# WKUP_CTRL_MMR1_CFG0 register map
Vendor: Texas Instruments
Registers are 32-bit, read-write, reset 0x0 unless marked. A register's access mark holds for its fields unless they carry their own. Offsets are as the file gives them; [hi:lo] are bit positions; lines under a group give offsets from that group; {n}, {i} and the like mark numbered series.

## WKUP_CTRL_MMR1_CFG0 (part 2 of 3)
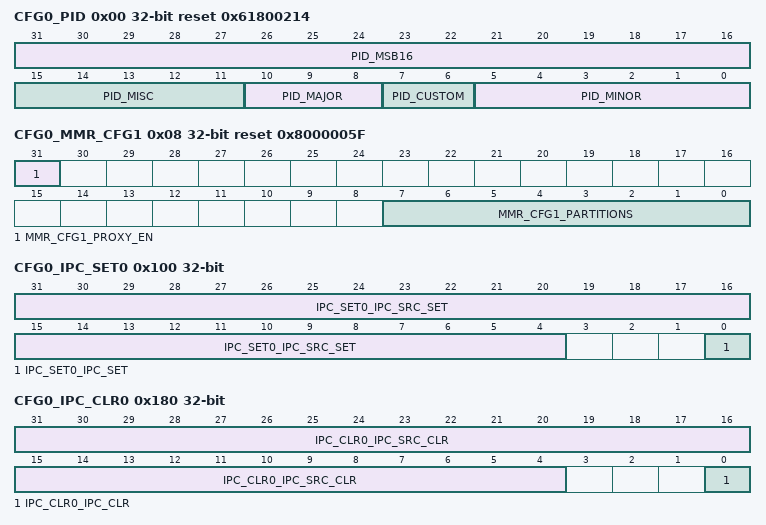
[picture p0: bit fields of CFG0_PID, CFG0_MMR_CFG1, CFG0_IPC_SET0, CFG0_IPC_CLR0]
0x00 CFG0_PID ro reset 0x61800214
  [31:16] PID_MSB16, [15:11] PID_MISC, [10:8] PID_MAJOR, [7:6] PID_CUSTOM, [5:0] PID_MINOR
0x08 CFG0_MMR_CFG1 ro reset 0x8000005F
  [31] MMR_CFG1_PROXY_EN — Proxy addressing activated
  [7:0] MMR_CFG1_PARTITIONS — Indicates present partitions
0x100 CFG0_IPC_SET0 access not given
  [31:4] IPC_SET0_IPC_SRC_SET — Read returns current value Write: 0 - No effect 1 - Sets both SRC_SETx and the SRC_CLRx bit in the corresponding IPC_CLR register (access R/W1TS)
  [0] IPC_SET0_IPC_SET — Read returns 0 Write: 0 - No effect 1 - Sets both the IPC_SET and the IPC_CLR bit in the corresponding IPC_CLR register (access R/W1TS)
0x180 CFG0_IPC_CLR0 access not given
  [31:4] IPC_CLR0_IPC_SRC_CLR — Read returns current value Write: 0 - No effect 1 - Clears both SRC_CLRx and the SRC_SETx bit in the corresponding IPC_GEN register (access R/W1TC)
  [0] IPC_CLR0_IPC_CLR — Read returns current value Write: 0 - No effect 1 - Clears both IPC_CLR and the IPC_SET bit in the corresponding IPC_SET register (access R/W1TC)
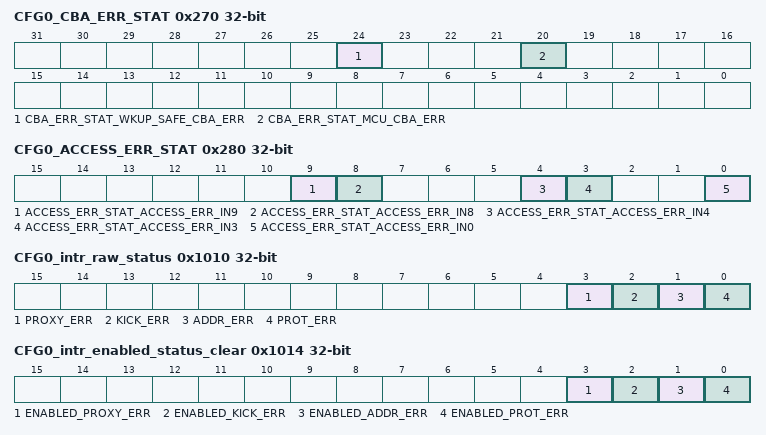
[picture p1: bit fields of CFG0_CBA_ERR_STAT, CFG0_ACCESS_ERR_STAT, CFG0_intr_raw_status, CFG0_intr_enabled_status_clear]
0x270 CFG0_CBA_ERR_STAT ro
  [24] CBA_ERR_STAT_WKUP_SAFE_CBA_ERR — Access Error from Wkup Safe CBASS
  [20] CBA_ERR_STAT_MCU_CBA_ERR — Access Error from MCU CBASS
0x280 CFG0_ACCESS_ERR_STAT ro
  [9] ACCESS_ERR_STAT_ACCESS_ERR_IN9 — Access Error Detected in MCU PadCfg MMR
  [8] ACCESS_ERR_STAT_ACCESS_ERR_IN8 — Access Error Detected in MCU Ctrl MMR
  [4] ACCESS_ERR_STAT_ACCESS_ERR_IN4 — Access Error Detected in MAIN PadCfg MMR
  [3] ACCESS_ERR_STAT_ACCESS_ERR_IN3 — Access Error Detected in MAIN Ctrl MMR
  [0] ACCESS_ERR_STAT_ACCESS_ERR_IN0 — Access Error Detected in WKUP Ctrl MMR
{0x1008+0x4000*i} CFG0_LOCK{i}_KICK0 (i=0..4)
  [31:0] LOCK{i}_KICK0 — - KICK0 component
{0x100C+0x4000*i} CFG0_LOCK{i}_KICK1 (i=0..4)
  [31:0] LOCK{i}_KICK1 — - KICK1 component
0x1010 CFG0_intr_raw_status access not given
  [3] PROXY_ERR — Proxy0 access violation error. Raw status is read. Write a 1 to set the status. Writing a 0 has no effect. (access R/W1TS)
  [2] KICK_ERR — Kick access violation error. Raw status is read. Write a 1 to set the status. Writing a 0 has no effect. (access R/W1TS)
  [1] ADDR_ERR — Addressing violation error. Raw status is read. Write a 1 to set the status. Writing a 0 has no effect. (access R/W1TS)
  [0] PROT_ERR — Protection violation error. Raw status is read. Write a 1 to set the status. Writing a 0 has no effect. (access R/W1TS)
0x1014 CFG0_intr_enabled_status_clear access not given
  [3] ENABLED_PROXY_ERR — Proxy0 access violation error. Enabled status is read. Write a 1 to clear the status. Writing a 0 has no effect. (access R/W1TC)
  [2] ENABLED_KICK_ERR — Kick access violation error. Enabled status is read. Write a 1 to clear the status. Writing a 0 has no effect. (access R/W1TC)
  [1] ENABLED_ADDR_ERR — Addressing violation error. Enabled status is read. Write a 1 to clear the status. Writing a 0 has no effect. (access R/W1TC)
  [0] ENABLED_PROT_ERR — Protection violation error. Enabled status is read. Write a 1 to clear the status. Writing a 0 has no effect. (access R/W1TC)
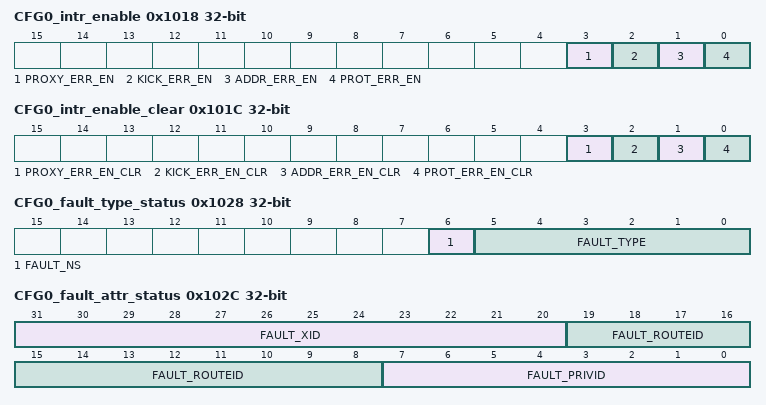
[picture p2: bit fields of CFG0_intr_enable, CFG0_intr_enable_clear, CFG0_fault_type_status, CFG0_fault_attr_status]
0x1018 CFG0_intr_enable access not given
  [3] PROXY_ERR_EN — Proxy0 access violation error enable. Write a 1 to set the enable. Writing a 0 has no effect. (access R/W1TS)
  [2] KICK_ERR_EN — Kick access violation error enable. Write a 1 to set the enable. Writing a 0 has no effect. (access R/W1TS)
  [1] ADDR_ERR_EN — Addressing violation error enable. Write a 1 to set the enable. Writing a 0 has no effect. (access R/W1TS)
  [0] PROT_ERR_EN — Protection violation error enable. Write a 1 to set the enable. Writing a 0 has no effect. (access R/W1TS)
0x101C CFG0_intr_enable_clear access not given
  [3] PROXY_ERR_EN_CLR — Proxy0 access violation error enable clear. Write a 1 to clear the enable. Writing a 0 has no effect. (access R/W1TC)
  [2] KICK_ERR_EN_CLR — Kick access violation error enable clear. Write a 1 to clear the enable. Writing a 0 has no effect. (access R/W1TC)
  [1] ADDR_ERR_EN_CLR — Addressing violation error enable clear. Write a 1 to clear the enable. Writing a 0 has no effect. (access R/W1TC)
  [0] PROT_ERR_EN_CLR — Protection violation error enable clear. Write a 1 to clear the enable. Writing a 0 has no effect. (access R/W1TC)
0x1020 CFG0_eoi
  [7:0] EOI_VECTOR — EOI vector value. Write this with interrupt distribution value in the chip.
0x1024 CFG0_fault_address ro
  [31:0] FAULT_ADDR — Fault Address.
0x1028 CFG0_fault_type_status ro
  [6] FAULT_NS — Non-secure access.
  [5:0] FAULT_TYPE — Fault Type 10_0000 = Supervisor read fault - priv = 1 dir = 1 dtype != 1 01_0000 = Supervisor write fault - priv = 1 dir = 0 00_1000 = Supervisor execute fault - priv = 1 dir = 1 dtype = 1 00_0100 = User read fault - priv = 0 dir = 1 dtype = 1 00_0010 = User write fault - priv = 0 dir = 0 00_0001 = User execute fault - priv = 0 dir = 1 dtype = 1 00_0000 = No fault
0x102C CFG0_fault_attr_status ro
  [31:20] FAULT_XID — XID.
  [19:8] FAULT_ROUTEID — Route ID.
  [7:0] FAULT_PRIVID — Privilege ID.
0x1030 CFG0_fault_clear wo
  [0] FAULT_CLR — Fault clear. Writing a 1 clears the current fault. Writing a 0 has no effect.
{0x1100+4i} CFG0_CLAIMREG_P0_R{i}_READONLY ro (i=0..5)
  [31:0] CLAIMREG_P0_R{i}_READONLY — Claim bits for Partition 0
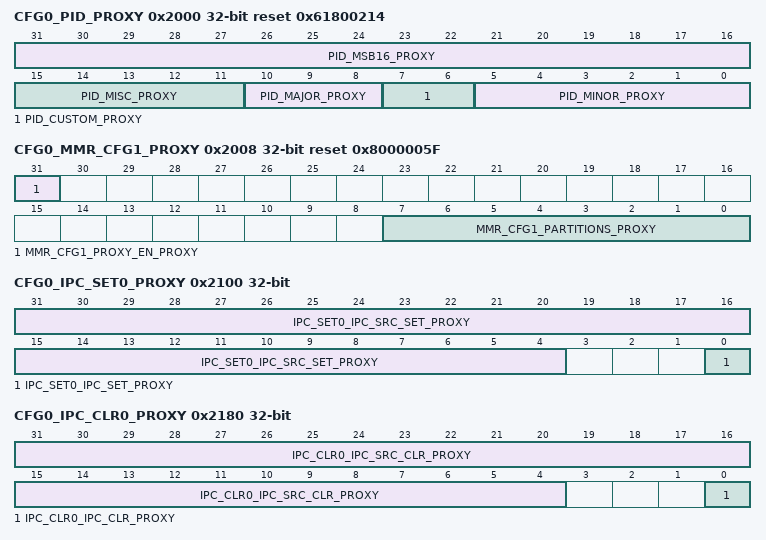
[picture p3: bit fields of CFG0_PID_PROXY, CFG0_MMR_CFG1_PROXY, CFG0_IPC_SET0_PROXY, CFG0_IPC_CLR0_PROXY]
0x2000 CFG0_PID_PROXY ro reset 0x61800214
  [31:16] PID_MSB16_PROXY, [15:11] PID_MISC_PROXY, [10:8] PID_MAJOR_PROXY, [7:6] PID_CUSTOM_PROXY, [5:0] PID_MINOR_PROXY
0x2008 CFG0_MMR_CFG1_PROXY ro reset 0x8000005F
  [31] MMR_CFG1_PROXY_EN_PROXY — Proxy addressing activated
  [7:0] MMR_CFG1_PARTITIONS_PROXY — Indicates present partitions
0x2100 CFG0_IPC_SET0_PROXY access not given
  [31:4] IPC_SET0_IPC_SRC_SET_PROXY — Read returns current value Write: 0 - No effect 1 - Sets both SRC_SETx and the SRC_CLRx bit in the corresponding IPC_CLR register (access R/W1TS)
  [0] IPC_SET0_IPC_SET_PROXY — Read returns 0 Write: 0 - No effect 1 - Sets both the IPC_SET and the IPC_CLR bit in the corresponding IPC_CLR register (access R/W1TS)
0x2180 CFG0_IPC_CLR0_PROXY access not given
  [31:4] IPC_CLR0_IPC_SRC_CLR_PROXY — Read returns current value Write: 0 - No effect 1 - Clears both SRC_CLRx and the SRC_SETx bit in the corresponding IPC_GEN register (access R/W1TC)
  [0] IPC_CLR0_IPC_CLR_PROXY — Read returns current value Write: 0 - No effect 1 - Clears both IPC_CLR and the IPC_SET bit in the corresponding IPC_SET register (access R/W1TC)
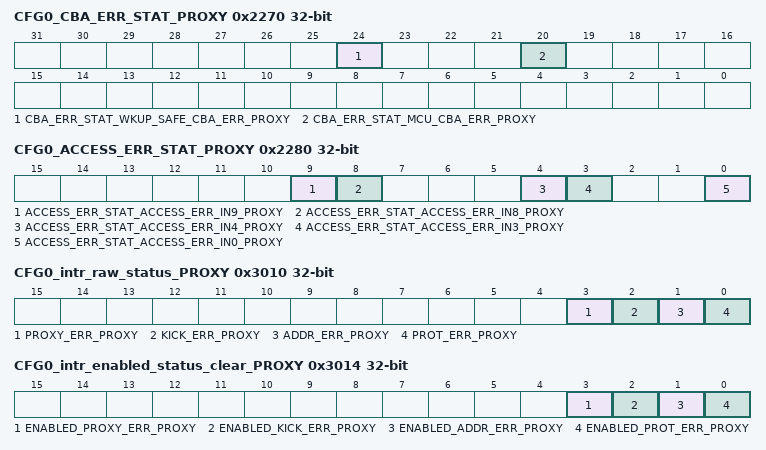
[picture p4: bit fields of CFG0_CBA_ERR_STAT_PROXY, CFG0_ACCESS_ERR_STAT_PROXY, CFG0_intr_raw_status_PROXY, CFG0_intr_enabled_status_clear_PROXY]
0x2270 CFG0_CBA_ERR_STAT_PROXY ro
  [24] CBA_ERR_STAT_WKUP_SAFE_CBA_ERR_PROXY — Access Error from Wkup Safe CBASS
  [20] CBA_ERR_STAT_MCU_CBA_ERR_PROXY — Access Error from MCU CBASS
0x2280 CFG0_ACCESS_ERR_STAT_PROXY ro
  [9] ACCESS_ERR_STAT_ACCESS_ERR_IN9_PROXY — Access Error Detected in MCU PadCfg MMR
  [8] ACCESS_ERR_STAT_ACCESS_ERR_IN8_PROXY — Access Error Detected in MCU Ctrl MMR
  [4] ACCESS_ERR_STAT_ACCESS_ERR_IN4_PROXY — Access Error Detected in MAIN PadCfg MMR
  [3] ACCESS_ERR_STAT_ACCESS_ERR_IN3_PROXY — Access Error Detected in MAIN Ctrl MMR
  [0] ACCESS_ERR_STAT_ACCESS_ERR_IN0_PROXY — Access Error Detected in WKUP Ctrl MMR
{0x3008+0x4000*i} CFG0_LOCK{i}_KICK0_PROXY (i=0..4)
  [31:0] LOCK{i}_KICK0_PROXY — - KICK0 component
{0x300C+0x4000*i} CFG0_LOCK{i}_KICK1_PROXY (i=0..4)
  [31:0] LOCK{i}_KICK1_PROXY — - KICK1 component
0x3010 CFG0_intr_raw_status_PROXY access not given
  [3] PROXY_ERR_PROXY — Proxy0 access violation error. Raw status is read. Write a 1 to set the status. Writing a 0 has no effect. (access R/W1TS)
  [2] KICK_ERR_PROXY — Kick access violation error. Raw status is read. Write a 1 to set the status. Writing a 0 has no effect. (access R/W1TS)
  [1] ADDR_ERR_PROXY — Addressing violation error. Raw status is read. Write a 1 to set the status. Writing a 0 has no effect. (access R/W1TS)
  [0] PROT_ERR_PROXY — Protection violation error. Raw status is read. Write a 1 to set the status. Writing a 0 has no effect. (access R/W1TS)
0x3014 CFG0_intr_enabled_status_clear_PROXY access not given
  [3] ENABLED_PROXY_ERR_PROXY — Proxy0 access violation error. Enabled status is read. Write a 1 to clear the status. Writing a 0 has no effect. (access R/W1TC)
  [2] ENABLED_KICK_ERR_PROXY — Kick access violation error. Enabled status is read. Write a 1 to clear the status. Writing a 0 has no effect. (access R/W1TC)
  [1] ENABLED_ADDR_ERR_PROXY — Addressing violation error. Enabled status is read. Write a 1 to clear the status. Writing a 0 has no effect. (access R/W1TC)
  [0] ENABLED_PROT_ERR_PROXY — Protection violation error. Enabled status is read. Write a 1 to clear the status. Writing a 0 has no effect. (access R/W1TC)
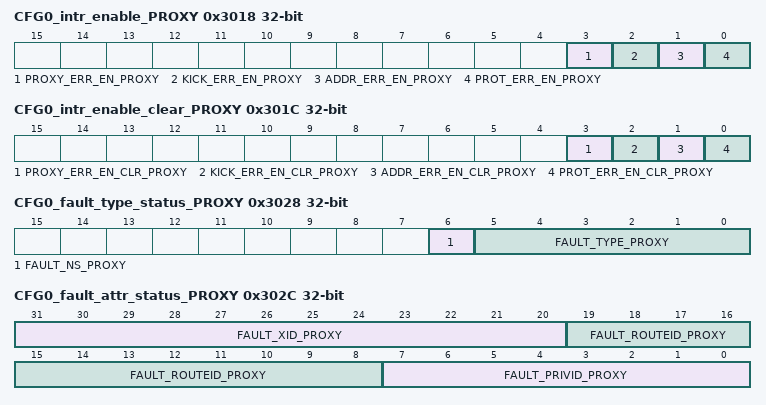
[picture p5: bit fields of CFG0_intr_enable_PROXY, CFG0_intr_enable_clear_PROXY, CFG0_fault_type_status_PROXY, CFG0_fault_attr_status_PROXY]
0x3018 CFG0_intr_enable_PROXY access not given
  [3] PROXY_ERR_EN_PROXY — Proxy0 access violation error enable. Write a 1 to set the enable. Writing a 0 has no effect. (access R/W1TS)
  [2] KICK_ERR_EN_PROXY — Kick access violation error enable. Write a 1 to set the enable. Writing a 0 has no effect. (access R/W1TS)
  [1] ADDR_ERR_EN_PROXY — Addressing violation error enable. Write a 1 to set the enable. Writing a 0 has no effect. (access R/W1TS)
  [0] PROT_ERR_EN_PROXY — Protection violation error enable. Write a 1 to set the enable. Writing a 0 has no effect. (access R/W1TS)
0x301C CFG0_intr_enable_clear_PROXY access not given
  [3] PROXY_ERR_EN_CLR_PROXY — Proxy0 access violation error enable clear. Write a 1 to clear the enable. Writing a 0 has no effect. (access R/W1TC)
  [2] KICK_ERR_EN_CLR_PROXY — Kick access violation error enable clear. Write a 1 to clear the enable. Writing a 0 has no effect. (access R/W1TC)
  [1] ADDR_ERR_EN_CLR_PROXY — Addressing violation error enable clear. Write a 1 to clear the enable. Writing a 0 has no effect. (access R/W1TC)
  [0] PROT_ERR_EN_CLR_PROXY — Protection violation error enable clear. Write a 1 to clear the enable. Writing a 0 has no effect. (access R/W1TC)
0x3020 CFG0_eoi_PROXY
  [7:0] EOI_VECTOR_PROXY — EOI vector value. Write this with interrupt distribution value in the chip.
0x3024 CFG0_fault_address_PROXY ro
  [31:0] FAULT_ADDR_PROXY — Fault Address.
0x3028 CFG0_fault_type_status_PROXY ro
  [6] FAULT_NS_PROXY — Non-secure access.
  [5:0] FAULT_TYPE_PROXY — Fault Type 10_0000 = Supervisor read fault - priv = 1 dir = 1 dtype != 1 01_0000 = Supervisor write fault - priv = 1 dir = 0 00_1000 = Supervisor execute fault - priv = 1 dir = 1 dtype = 1 00_0100 = User read fault - priv = 0 dir = 1 dtype = 1 00_0010 = User write fault - priv = 0 dir = 0 00_0001 = User execute fault - priv = 0 dir = 1 dtype = 1 00_0000 = No fault
0x302C CFG0_fault_attr_status_PROXY ro
  [31:20] FAULT_XID_PROXY — XID.
  [19:8] FAULT_ROUTEID_PROXY — Route ID.
  [7:0] FAULT_PRIVID_PROXY — Privilege ID.
0x3030 CFG0_fault_clear_PROXY wo
  [0] FAULT_CLR_PROXY — Fault clear. Writing a 1 clears the current fault. Writing a 0 has no effect.
{0x3100+4i} CFG0_CLAIMREG_P0_R{i} (i=0..5)
  [31:0] CLAIMREG_P0_R{i} — Claim bits for Partition 0
0x4020 CFG0_MCU_GPIO_CTRL
  [0] MCU_GPIO_CTRL_WAKEN — Activates MCU_GPIO wakeup event operation by controling the MCU_GPIO LPSC clockstop_ack behavior. Field values (Others are reserved): 1'b0 - No MCU_GPIO wakeup support. MCU_GPIO vbus clock is gated on clkstop_ack from MCU_GPIO to LPSC 1'b1 - MCU_GPIO wakeup activated. MCU_GPIO vbus clock is NOT gated on LPSC clockstop_req. MCU_GPIO LPSC clkstop_ack input is driven by clkstop_req output.
{0x4080+4i} CFG0_DBOUNCE_CFG{i} (i=1..6)
  [5:0] DBOUNCE_CFG{i}_DB_CFG — Configures the debounce period used for I/Os with debounce_sel{i} activated. See the AM62xx IO Integration Spec for Detail (https://pds.design.ti.com/cgi-bin/viewdocs?pds_bgid=21&docconfigid=745&filtertitle=2719&filteritem=14547)
0x40A0 CFG0_TEMP_DIODE_TRIM ro
  [13:0] TEMP_DIODE_TRIM_TRIM — Sets the diode non-ideality factor (n), starting from 100th place decimal and going down
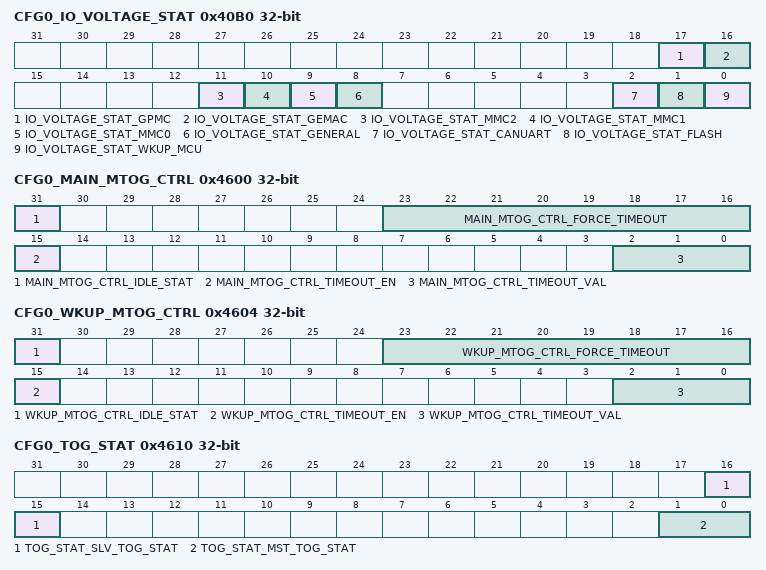
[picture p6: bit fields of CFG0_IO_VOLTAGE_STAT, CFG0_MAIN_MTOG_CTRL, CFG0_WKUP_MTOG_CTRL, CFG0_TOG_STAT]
0x40B0 CFG0_IO_VOLTAGE_STAT ro
  [17] IO_VOLTAGE_STAT_GPMC — Indicates the voltage for the GPMC I/O group (VDDSHV3) 0 - I/O group is set for 1.8V 1 - I/O group is set for 3.3V Field values (others are reserved): 1'b0 - I/O group is set for 3.3V 1'b1 - I/O group is set for 1.8V
  [16] IO_VOLTAGE_STAT_GEMAC — Indicates the voltage for the GEMAC I/O group (VDDSHV2) 0 - I/O group is set for 1.8V 1 - I/O group is set for 3.3V
  [11] IO_VOLTAGE_STAT_MMC2 — Indicates the voltage for the MMC2 I/O group (VDDSHV6) 0 - I/O group is set for 1.8V 1 - I/O group is set for 3.3V
  [10] IO_VOLTAGE_STAT_MMC1 — Indicates the voltage for the MMC1 I/O group (VDDSHV5) 0 - I/O group is set for 1.8V 1 - I/O group is set for 3.3V
  [9] IO_VOLTAGE_STAT_MMC0 — Indicates the voltage for the MMC0 I/O group (VDDSHV4) 0 - I/O group is set for 1.8V 1 - I/O group is set for 3.3V
  [8] IO_VOLTAGE_STAT_GENERAL — Indicates the voltage for the General I/O group (VDDSHV0) 0 - I/O group is set for 1.8V 1 - I/O group is set for 3.3V
  [2] IO_VOLTAGE_STAT_CANUART — Indicates the voltage for the CANUART I/O group (VDDSHV_WKUP) 0 - I/O group is set for 1.8V 1 - I/O group is set for 3.3V
  [1] IO_VOLTAGE_STAT_FLASH — Indicates the voltage for the Flash I/O group (VDDSHV1) 0 - I/O group is set for 1.8V 1 - I/O group is set for 3.3V
  [0] IO_VOLTAGE_STAT_WKUP_MCU — Indicates the voltage for the WKUP_MCU I/O group (VDDSHV_MCU) 0 - I/O group is set for 1.8V 1 - I/O group is set for 3.3V
0x4204 CFG0_MCU_TIMER1_CTRL
  [8] MCU_TIMER1_CTRL_CASCADE_EN — Activates cascading of TIMER1 to TIMER0
0x420C CFG0_MCU_TIMER3_CTRL
  [8] MCU_TIMER3_CTRL_CASCADE_EN — Activates cascading of TIMER3 to TIMER2
0x42E0 CFG0_MCU_I2C0_CTRL
  [0] MCU_I2C0_CTRL_HS_MCS_EN — HS Mode controller current source activate. When set, activates the current-source pull-up on the SCL output. Only one controller on the I2C bus should activate SCL current sourcing.
0x4600 CFG0_MAIN_MTOG_CTRL access per field
  [31] MAIN_MTOG_CTRL_IDLE_STAT ro — Idle Status: When high, indicates MTOG0 is idle Field values (others are reserved): 1'b0 - Gasket is Not Idle 1'b1 - Gasket is Idle
  [23:16] MAIN_MTOG_CTRL_FORCE_TIMEOUT rw — Force Timout This is a fault tolerant bitfield. Forces a flush of the interface transactions. This bitfield is only relevant if timeout_en=1. After forcing a timeout by writing the encoded value, the force_timeout and timeout_en bitfields mut be cleared to clear the timeout before re-enabling the gasket. 8'h95 - Force a gasket timeout All others - Normal operation Field values (others are reserved): 8'h95 - This is a fault tolerant bitfield. Forces a flush of the interface transactions. This bitfield is only relevant if timeout_en=1. After forcing a timeout by writing the encoded value, the force_timeout and timeout_en bitfields mut be cleared to clear the timeout before re-enabling the gasket. 8'h00 - Other Values Have No Effect
  [15] MAIN_MTOG_CTRL_TIMEOUT_EN rw — Timeout Activate 1'b0 - Deactivate the gasket. Clear the interrupt and reset the counter 1'b1 - Activate the timeout gasket functions Field values (others are reserved): 1'b0 - Deactivate the gasket. Clear the interrupt and reset the counter. 1'b1 - Activate Gasket Functions
  [2:0] MAIN_MTOG_CTRL_TIMEOUT_VAL rw — Gasket Timeout Value Selects the number of clock cycles before the interface is considered to have timed out
0x4604 CFG0_WKUP_MTOG_CTRL access per field
  [31] WKUP_MTOG_CTRL_IDLE_STAT ro — Idle Status Field values (others are reserved): 1'b0 - Gasket is Not Idle 1'b1 - Gasket is Idle
  [23:16] WKUP_MTOG_CTRL_FORCE_TIMEOUT rw — Force Timout This is a fault tolerant bitfield. Forces a flush of the interface transactions. This bitfield is only relevant if timeout_en=1. After forcing a timeout by writing the encoded value, the force_timeout and timeout_en bitfields mut be cleared to clear the timeout before re-enabling the gasket. 8'h95 - Force a gasket timeout All others - Normal operation Field values (others are reserved): 8'h95 - This is a fault tolerant bitfield. Forces a flush of the interface transactions. This bitfield is only relevant if timeout_en=1. After forcing a timeout by writing the encoded value, the force_timeout and timeout_en bitfields mut be cleared to clear the timeout before re-enabling the gasket. 8'h00 - Other Values Have No Effect
  [15] WKUP_MTOG_CTRL_TIMEOUT_EN rw — Timeout Activate 1'b0 - Deactivate the gasket. Clear the interrupt and reset the counter 1'b1 - Activate the timeout gasket functions Field values (others are reserved): 1'b0 - Deactivate the gasket. Clear the interrupt and reset the counter. 1'b1 - Activate Gasket Functions
  [2:0] WKUP_MTOG_CTRL_TIMEOUT_VAL rw — Gasket Timeout Value Selects the number of clock cycles before the interface is considered to have timed out
0x4610 CFG0_TOG_STAT ro
  [16:15] TOG_STAT_SLV_TOG_STAT — Error Status of target Timeout Gaskets slv_tog_statundefined - Error status of mcu2central timeout gasket slv_tog_statundefined - Error status of mcu2dm timeout gasket
  [1:0] TOG_STAT_MST_TOG_STAT — Error Status of Controller Timeout Gaskets mst_tog_statundefined - Error status of central2mcu timeout gasket mst_tog_statundefined - Error status of dm2ws timeout gasket
{0x5100+4i} CFG0_CLAIMREG_P1_R{i}_READONLY ro (i=0..12)
  [31:0] CLAIMREG_P1_R{i}_READONLY — Claim bits for Partition 1
0x6020 CFG0_MCU_GPIO_CTRL_PROXY
  [0] MCU_GPIO_CTRL_WAKEN_PROXY — Activates MCU_GPIO wakeup event operation by controling the MCU_GPIO LPSC clockstop_ack behavior. Field values (Others are reserved): 1'b0 - No MCU_GPIO wakeup support. MCU_GPIO vbus clock is gated on clkstop_ack from MCU_GPIO to LPSC 1'b1 - MCU_GPIO wakeup activated. MCU_GPIO vbus clock is NOT gated on LPSC clockstop_req. MCU_GPIO LPSC clkstop_ack input is driven by clkstop_req output.
{0x6080+4i} CFG0_DBOUNCE_CFG{i}_PROXY (i=1..6)
  [5:0] DBOUNCE_CFG{i}_DB_CFG_PROXY — Configures the debounce period used for I/Os with debounce_sel{i} activated. See the AM62xx IO Integration Spec for Detail (https://pds.design.ti.com/cgi-bin/viewdocs?pds_bgid=21&docconfigid=745&filtertitle=2719&filteritem=14547)
0x60A0 CFG0_TEMP_DIODE_TRIM_PROXY ro
  [13:0] TEMP_DIODE_TRIM_TRIM_PROXY — Sets the diode non-ideality factor (n), starting from 100th place decimal and going down
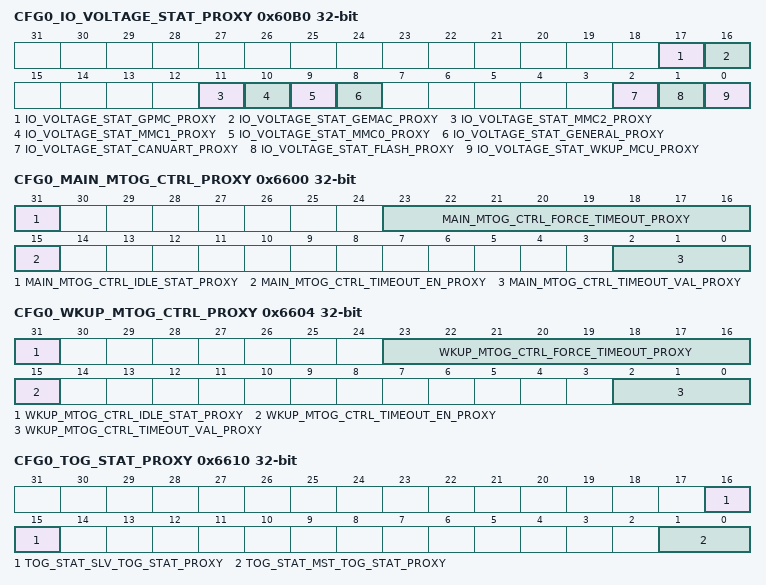
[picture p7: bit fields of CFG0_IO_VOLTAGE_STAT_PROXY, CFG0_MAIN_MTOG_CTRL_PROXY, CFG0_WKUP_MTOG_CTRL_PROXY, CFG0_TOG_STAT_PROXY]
0x60B0 CFG0_IO_VOLTAGE_STAT_PROXY ro
  [17] IO_VOLTAGE_STAT_GPMC_PROXY — Indicates the voltage for the GPMC I/O group (VDDSHV3) 0 - I/O group is set for 1.8V 1 - I/O group is set for 3.3V Field values (others are reserved): 1'b0 - I/O group is set for 3.3V 1'b1 - I/O group is set for 1.8V
  [16] IO_VOLTAGE_STAT_GEMAC_PROXY — Indicates the voltage for the GEMAC I/O group (VDDSHV2) 0 - I/O group is set for 1.8V 1 - I/O group is set for 3.3V
  [11] IO_VOLTAGE_STAT_MMC2_PROXY — Indicates the voltage for the MMC2 I/O group (VDDSHV6) 0 - I/O group is set for 1.8V 1 - I/O group is set for 3.3V
  [10] IO_VOLTAGE_STAT_MMC1_PROXY — Indicates the voltage for the MMC1 I/O group (VDDSHV5) 0 - I/O group is set for 1.8V 1 - I/O group is set for 3.3V
  [9] IO_VOLTAGE_STAT_MMC0_PROXY — Indicates the voltage for the MMC0 I/O group (VDDSHV4) 0 - I/O group is set for 1.8V 1 - I/O group is set for 3.3V
  [8] IO_VOLTAGE_STAT_GENERAL_PROXY — Indicates the voltage for the General I/O group (VDDSHV0) 0 - I/O group is set for 1.8V 1 - I/O group is set for 3.3V
  [2] IO_VOLTAGE_STAT_CANUART_PROXY — Indicates the voltage for the CANUART I/O group (VDDSHV_WKUP) 0 - I/O group is set for 1.8V 1 - I/O group is set for 3.3V
  [1] IO_VOLTAGE_STAT_FLASH_PROXY — Indicates the voltage for the Flash I/O group (VDDSHV1) 0 - I/O group is set for 1.8V 1 - I/O group is set for 3.3V
  [0] IO_VOLTAGE_STAT_WKUP_MCU_PROXY — Indicates the voltage for the WKUP_MCU I/O group (VDDSHV_MCU) 0 - I/O group is set for 1.8V 1 - I/O group is set for 3.3V
0x6204 CFG0_MCU_TIMER1_CTRL_PROXY
  [8] MCU_TIMER1_CTRL_CASCADE_EN_PROXY — Activates cascading of TIMER1 to TIMER0
0x620C CFG0_MCU_TIMER3_CTRL_PROXY
  [8] MCU_TIMER3_CTRL_CASCADE_EN_PROXY — Activates cascading of TIMER3 to TIMER2
0x62E0 CFG0_MCU_I2C0_CTRL_PROXY
  [0] MCU_I2C0_CTRL_HS_MCS_EN_PROXY — HS Mode controller current source activate. When set, activates the current-source pull-up on the SCL output. Only one controller on the I2C bus should activate SCL current sourcing.
0x6600 CFG0_MAIN_MTOG_CTRL_PROXY access per field
  [31] MAIN_MTOG_CTRL_IDLE_STAT_PROXY ro — Idle Status: When high, indicates MTOG0 is idle Field values (others are reserved): 1'b0 - Gasket is Not Idle 1'b1 - Gasket is Idle
  [23:16] MAIN_MTOG_CTRL_FORCE_TIMEOUT_PROXY rw — Force Timout This is a fault tolerant bitfield. Forces a flush of the interface transactions. This bitfield is only relevant if timeout_en=1. After forcing a timeout by writing the encoded value, the force_timeout and timeout_en bitfields mut be cleared to clear the timeout before re-enabling the gasket. 8'h95 - Force a gasket timeout All others - Normal operation Field values (others are reserved): 8'h95 - This is a fault tolerant bitfield. Forces a flush of the interface transactions. This bitfield is only relevant if timeout_en=1. After forcing a timeout by writing the encoded value, the force_timeout and timeout_en bitfields mut be cleared to clear the timeout before re-enabling the gasket. 8'h00 - Other Values Have No Effect
  [15] MAIN_MTOG_CTRL_TIMEOUT_EN_PROXY rw — Timeout Activate 1'b0 - Deactivate the gasket. Clear the interrupt and reset the counter 1'b1 - Activate the timeout gasket functions Field values (others are reserved): 1'b0 - Deactivate the gasket. Clear the interrupt and reset the counter. 1'b1 - Activate Gasket Functions
  [2:0] MAIN_MTOG_CTRL_TIMEOUT_VAL_PROXY rw — Gasket Timeout Value Selects the number of clock cycles before the interface is considered to have timed out
0x6604 CFG0_WKUP_MTOG_CTRL_PROXY access per field
  [31] WKUP_MTOG_CTRL_IDLE_STAT_PROXY ro — Idle Status Field values (others are reserved): 1'b0 - Gasket is Not Idle 1'b1 - Gasket is Idle
  [23:16] WKUP_MTOG_CTRL_FORCE_TIMEOUT_PROXY rw — Force Timout This is a fault tolerant bitfield. Forces a flush of the interface transactions. This bitfield is only relevant if timeout_en=1. After forcing a timeout by writing the encoded value, the force_timeout and timeout_en bitfields mut be cleared to clear the timeout before re-enabling the gasket. 8'h95 - Force a gasket timeout All others - Normal operation Field values (others are reserved): 8'h95 - This is a fault tolerant bitfield. Forces a flush of the interface transactions. This bitfield is only relevant if timeout_en=1. After forcing a timeout by writing the encoded value, the force_timeout and timeout_en bitfields mut be cleared to clear the timeout before re-enabling the gasket. 8'h00 - Other Values Have No Effect
  [15] WKUP_MTOG_CTRL_TIMEOUT_EN_PROXY rw — Timeout Activate 1'b0 - Deactivate the gasket. Clear the interrupt and reset the counter 1'b1 - Activate the timeout gasket functions Field values (others are reserved): 1'b0 - Deactivate the gasket. Clear the interrupt and reset the counter. 1'b1 - Activate Gasket Functions
  [2:0] WKUP_MTOG_CTRL_TIMEOUT_VAL_PROXY rw — Gasket Timeout Value Selects the number of clock cycles before the interface is considered to have timed out
0x6610 CFG0_TOG_STAT_PROXY ro
  [16:15] TOG_STAT_SLV_TOG_STAT_PROXY — Error Status of target Timeout Gaskets slv_tog_statundefined - Error status of mcu2central timeout gasket slv_tog_statundefined - Error status of mcu2dm timeout gasket
  [1:0] TOG_STAT_MST_TOG_STAT_PROXY — Error Status of Controller Timeout Gaskets mst_tog_statundefined - Error status of central2mcu timeout gasket mst_tog_statundefined - Error status of dm2ws timeout gasket
{0x7100+4i} CFG0_CLAIMREG_P1_R{i} (i=0..12)
  [31:0] CLAIMREG_P1_R{i} — Claim bits for Partition 1
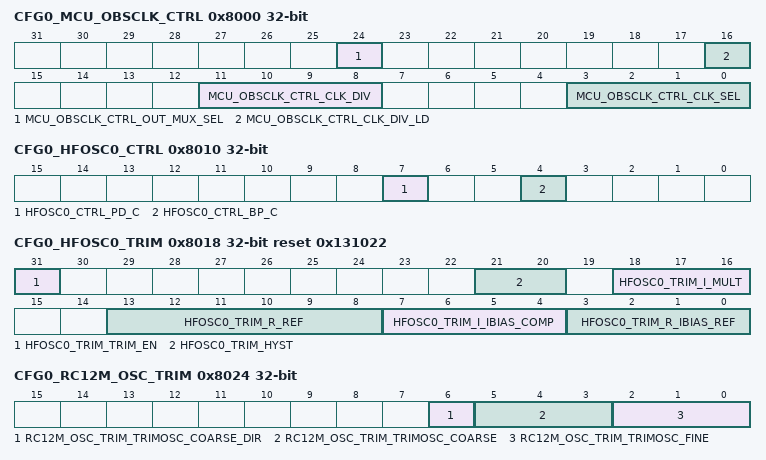
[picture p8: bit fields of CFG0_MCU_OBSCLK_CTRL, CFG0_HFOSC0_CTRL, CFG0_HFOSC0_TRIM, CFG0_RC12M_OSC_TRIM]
0x8000 CFG0_MCU_OBSCLK_CTRL
  [24] MCU_OBSCLK_CTRL_OUT_MUX_SEL — MCU_OBSCLK pin output mux selection. Note, when HFOSC0_CLK is selected (1'b1) the MCU_OBSCLK_CTRL_clk_sel field must be programmed to 4'b0001. 1'b0 - The output of the MCU_OBSCLK output divider is output on the pin 1'b1 - HFOSC0_CLK is output on the pin
  [16] MCU_OBSCLK_CTRL_CLK_DIV_LD — Load the output divider value Writing 1 to this bit will generate a load pulse to load the OBSCLK divider value. This bit can be cleared but must not be set in the same write cycle in which the clk_div value is changed.
  [11:8] MCU_OBSCLK_CTRL_CLK_DIV — MCU_OBSCLK pin clock selection output divider Output clock is divided by clk_div+1
  [3:0] MCU_OBSCLK_CTRL_CLK_SEL — MCU_OBSCLK pin clock selection Field values (others are reserved): 4'b0000 - CLK_12M_RC 4'b0001 - '0' 4'b0010 - MCU_PLL0_HSDIV0_CLKOUT 4'b0011 - MCU_PLL0_HSDIV4_CLKOUT 4'b0100 - MCU_PLLCTRL_OBSCLK 4'b0101 - CLK_32K 4'b0110 - HFOSC0_CLKOUT 4'b0111 - HFOSC0_CLKOUT_32K 4'b1000 - MCU_SYSCLK0 4'b1001 - DEVICE_CLKOUT_32K
0x8010 CFG0_HFOSC0_CTRL
  [7] HFOSC0_CTRL_PD_C — Oscillator powerdown control. When set, oscillator is deactivated. Oscillator output is tristated if bp_c=0
  [4] HFOSC0_CTRL_BP_C — Reserved - Must Write '0'
0x8018 CFG0_HFOSC0_TRIM reset 0x131022
  [31] HFOSC0_TRIM_TRIM_EN — Apply MMR values to OSC trim inputs instead of tie-offs
  [21:20] HFOSC0_TRIM_HYST — Sets comparator hysterisis
  [18:16] HFOSC0_TRIM_I_MULT — AGC AMP current multiplication gain
  [13:8] HFOSC0_TRIM_R_REF — Sets the AMP AGC bias current
  [7:4] HFOSC0_TRIM_I_IBIAS_COMP — Sets the COMP bias current
  [3:0] HFOSC0_TRIM_R_IBIAS_REF — Sets the base IBIAS reference
0x8020 CFG0_HFOSC0_STAT ro
  [0] HFOSC0_STAT_DS_ON_WFI_STAT — Allows MCU to monitor the DM attempting a Deep Sleep
0x8024 CFG0_RC12M_OSC_TRIM
  [6] RC12M_OSC_TRIM_TRIMOSC_COARSE_DIR — Coarse adjustment direction. If output is greater than 12.5 0 - Coarse adjustment decreases frequency 1 - Coarse adjustment increases frequency
  [5:3] RC12M_OSC_TRIM_TRIMOSC_COARSE — Coarse adjustment. Frequency is decreased or increased by 1.25 MHz per value based on the trimosc_coarse_dir value.
  [2:0] RC12M_OSC_TRIM_TRIMOSC_FINE — Fine adjustment. Decreases the frequency by 250 KHz per value.
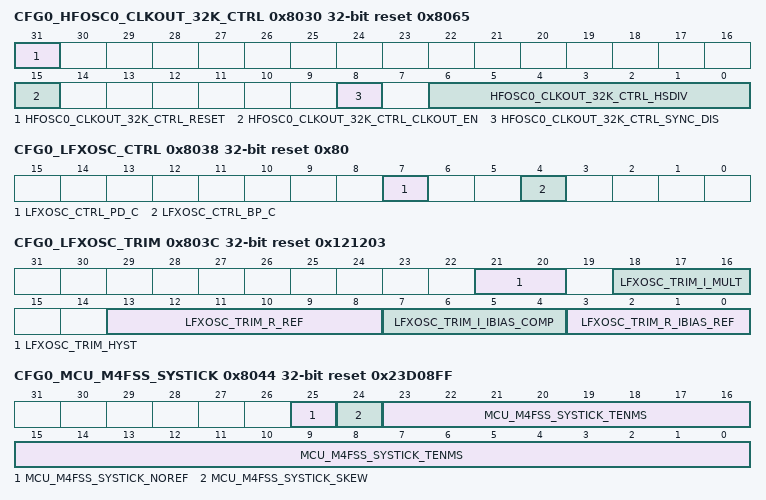
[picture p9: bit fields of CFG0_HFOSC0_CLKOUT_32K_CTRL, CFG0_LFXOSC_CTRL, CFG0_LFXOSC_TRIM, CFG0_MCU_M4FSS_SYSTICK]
0x8030 CFG0_HFOSC0_CLKOUT_32K_CTRL reset 0x8065
  [31] HFOSC0_CLKOUT_32K_CTRL_RESET — Asynchronous Divider Reset 1 = Divider is Reset, HFOSC0_CLKOUT32K reset. 0 = Divider out of reset, HFOSC0_CLKOUT_32K running.
  [15] HFOSC0_CLKOUT_32K_CTRL_CLKOUT_EN — HFOSC0_CLKOUT_32K activate: 0 = Synchronously Deactivate HFOSC0_CLKOUT_32KHz 1 = Synchronously Activate HFOSC0_CKLKOUT_32KHz
  [8] HFOSC0_CLKOUT_32K_CTRL_SYNC_DIS — HFOSC0_CLKOUT_32K Synchronize Deactivate 0 = Divider Updates are shadowed and take effect on counter reset. 1 = Divider Updates are immediate and hazardous Do not set this bit to 1'b1 during normal use.
  [6:0] HFOSC0_CLKOUT_32K_CTRL_HSDIV — HFOSC0_CLKOUT_32K divider: HFOSC0_CLKKOUT_32K Frequency = HFOSC0 Frequency / [8 * (hsdiv + 1)] Ex. HFOSC0 Frequency = 26MHz. hsdiv = 101 (Default) HFOSC0_CLKOUT_32K = 26MHz / (8 * (101+1)) = 26MHz / 816 = 31.9 KHz
0x8038 CFG0_LFXOSC_CTRL reset 0x80
  [7] LFXOSC_CTRL_PD_C — Oscillator powerdown control. When set, oscillator is deactivated. Oscillator output is tristated if bp_c=0
  [4] LFXOSC_CTRL_BP_C — Oscillator bypass control. When set, oscillator is in bypass mode
0x803C CFG0_LFXOSC_TRIM reset 0x121203
  [21:20] LFXOSC_TRIM_HYST — Sets comparator hysterisis Field values (others are reserved): 2'b00 - Hysteresis deactivated 2'b01 - Type 1 hysteresis activated (Default) 2'b10 - Type 2 hysteresis activated 2'b11 - Both types 1 & 2 hysteresis activated
  [18:16] LFXOSC_TRIM_I_MULT — AGC AMP current multiplication gain Field values (others are reserved): 3'b000 - 3x AMP_AGC IBIAS 3'b001 - 4x AMP_AGC IBIAS 3'b010 - 5x AMP_AGC IBIAS (Default) 3'b011 - 6x AMP_AGC IBIAS 3'b100 - 7x AMP_AGC IBIAS 3'b101 - 8x AMP_AGC IBIAS 3'b110 - 9x AMP_AGC IBIAS 3'b111 - 10x AMP_AGC IBIAS
  [13:8] LFXOSC_TRIM_R_REF — Sets the AMP AGC bias current Field values (others are reserved): 6'b000000 - 0 K Ohm 6'b000001 - 24 K Ohm 6'b000010 - 48 K Ohm 6'b000011 - 73 K Ohm 6'b000100 - 97 K Ohm 6'b000101 - 121 K Ohm 6'b000110 - 145 K Ohm 6'b000111 - 169 K Ohm 6'b001000 - 193 K Ohm 6'b001001 - 218 K Ohm 6'b001010 - 242 K Ohm 6'b001011 - 266 K Ohm 6'b001100 - 290 K Ohm 6'b001101 - 314 K Ohm 6'b001110 - 338 K Ohm 6'b001111 - 363 K Ohm 6'b010000 - 387 K Ohm 6'b010001 - 411 K Ohm 6'b010010 - 435 K Ohm (Default) 6'b010011 - 459 K Ohm 6'b010100 - 483 K Ohm 6'b010101 - 508 K Ohm 6'b010110 - 532 K Ohm 6'b010111 - 556 K Ohm 6'b011000 - 580 K Ohm 6'b011001 - 604 K Ohm 6'b011010 - 628 K Ohm 6'b011011 - 653 K Ohm 6'b011100 - 677 K Ohm 6'b011101 - 701 K Ohm 6'b011110 - 725 K Ohm 6'b011111 - 749 K Ohm 6'b100000 - 773 K Ohm 6'b100001 - 798 K Ohm 6'b100010 - 822 K Ohm 6'b100011 - 846 K Ohm 6'b100100 - 870 K Ohm 6'b100101 - 894 K Ohm 6'b100110 - 918 K Ohm 6'b100111 - 943 K Ohm 6'b101000 - 967 K Ohm 6'b101001 - 991 K Ohm 6'b101010 - 1015 K Ohm 6'b101011 - 1039 K Ohm 6'b101100 - 1063 K Ohm 6'b101101 - 1088 K Ohm 6'b101110 - 1112 K Ohm 6'b101111 - 1136 K Ohm 6'b110000 - 1160 K Ohm 6'b110001 - 1184 K Ohm 6'b110010 - 1208 K Ohm 6'b110011 - 1233 K Ohm 6'b110100 - 1257 K Ohm 6'b110101 - 1281 K Ohm 6'b110110 - 1305 K Ohm 6'b110111 - 1329 K Ohm 6'b111000 - 1353 K Ohm 6'b111001 - 1378 K Ohm 6'b111010 - 1402 K Ohm 6'b111011 - 1426 K Ohm 6'b111100 - 1450 K Ohm 6'b111101 - 1474 K Ohm 6'b111110 - 1498 K Ohm 6'b111111 - 1523 K Ohm
  [7:4] LFXOSC_TRIM_I_IBIAS_COMP — Sets the COMP bias current Field values (others are reserved): 4'b0000 - Base IBIAS ref x2 4'b0001 - Base IBIAS ref x3 4'b0010 - Base IBIAS ref x4 4'b0011 - Base IBIAS ref x5 4'b0100 - Base IBIAS ref x6 4'b0101 - Base IBIAS ref x7 4'b0110 - Base IBIAS ref x8 4'b0111 - Base IBIAS ref x9 4'b1000 - Base IBIAS ref x10 4'b1001 - Base IBIAS ref x11 4'b1010 - Base IBIAS ref x12 4'b1011 - Base IBIAS ref x13 4'b1100 - Base IBIAS ref x14 4'b1101 - Base IBIAS ref x15 4'b1110 - Base IBIAS ref x16 4'b1111 - Base IBIAS ref x17
  [3:0] LFXOSC_TRIM_R_IBIAS_REF — Sets the base IBIAS reference Field values (others are reserved): 4'b0000 - 512 K Ohm 4'b0001 - 576 K Ohm 4'b0010 - 640 K Ohm 4'b0011 - 704 K Ohm (Default) 4'b0100 - 768 K Ohm 4'b0101 - 832 K Ohm 4'b0110 - 896 K Ohm 4'b0111 - 960 K Ohm 4'b1000 - 1024 K Ohm 4'b1001 - 1088 K Ohm 4'b1010 - 1152 K Ohm 4'b1011 - 1216 K Ohm 4'b1100 - 1280 K Ohm 4'b1101 - 1344 K Ohm 4'b1110 - 1408 K Ohm 4'b1111 - 1472 K Ohm
0x8040 CFG0_MCU_M4FSS_CLKSEL
  [0] MCU_M4FSS_CLKSEL_M4FSS_CLKSEL — Selects the Clock Divider for M4FSS 0 = MCU_SYSCLK0 1 = MCU_SYSCLK0 / 2
0x8044 CFG0_MCU_M4FSS_SYSTICK access per field reset 0x23D08FF
  [25] MCU_M4FSS_SYSTICK_NOREF ro — No External Reference Clock for SysTick is available
  [24] MCU_M4FSS_SYSTICK_SKEW rw — Indicates whether or not the M4FSS free running clock divided by TENMS produces a 100Hz tick exactly Field values (others are reserved): 1'b0 - Divider produces exactly a 100 Hz SysTick 1'b1 - The SysTick Frequency is not exactly 100 Hz
  [23:0] MCU_M4FSS_SYSTICK_TENMS rw — Integer Divider Value that produces a 100Hz SysTick from the M4FSS Clock Frequency. Default is 3,999,999 (4M - 1) to produce a 100Hz clock from a 400 MHz M4FSS Clock.
